VERSION ""

NS_ :

BS_:

BU_: C50 TC_GPS_TELEM PDM MM5 DRIVERDISPLAY M400

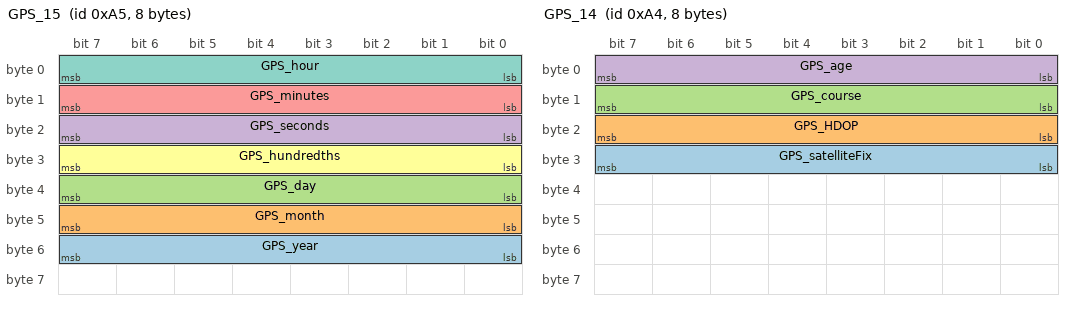
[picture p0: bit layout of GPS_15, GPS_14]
BO_ 165 GPS_15: 8 Vector__XXX
 SG_ GPS_year : 48|8@1+ (1,0) [0|0] "" Vector__XXX
 SG_ GPS_month : 40|8@1+ (1,0) [0|0] "" Vector__XXX
 SG_ GPS_day : 32|8@1+ (1,0) [0|0] "" Vector__XXX
 SG_ GPS_seconds : 16|8@1+ (1,0) [0|0] "secs" Vector__XXX
 SG_ GPS_minutes : 8|8@1+ (1,0) [0|0] "mins" Vector__XXX
 SG_ GPS_hundredths : 24|8@1+ (1,0) [0|0] "" Vector__XXX
 SG_ GPS_hour : 0|8@1+ (1,0) [0|0] "hrs" Vector__XXX

BO_ 164 GPS_14: 8 Vector__XXX
 SG_ GPS_satelliteFix : 24|8@1+ (1,0) [0|0] "" Vector__XXX
 SG_ GPS_HDOP : 16|8@1+ (1,0) [0|0] "" Vector__XXX
 SG_ GPS_course : 8|8@1+ (1,0) [0|0] "" Vector__XXX
 SG_ GPS_age : 0|8@1+ (1,0) [0|0] "" Vector__XXX

BO_ 163 GPS_13: 8 Vector__XXX
 SG_ GPS_speed : 32|32@1+ (1,0) [0|0] "mph" Vector__XXX
 SG_ GPS_longitude : 0|32@1- (1,0) [0|0] "degrees" Vector__XXX

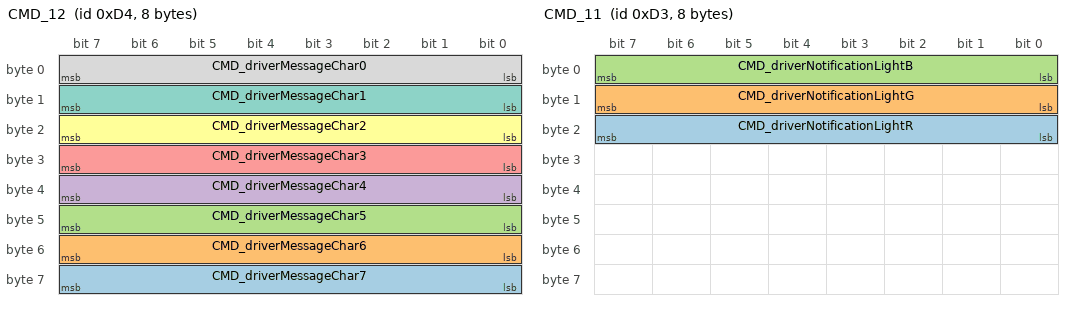
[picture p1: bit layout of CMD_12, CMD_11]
BO_ 212 CMD_12: 8 Vector__XXX
 SG_ CMD_driverMessageChar7 : 56|8@1+ (1,0) [0|255] "Duty Cycle" Vector__XXX
 SG_ CMD_driverMessageChar6 : 48|8@1+ (1,0) [0|255] "Duty Cycle" Vector__XXX
 SG_ CMD_driverMessageChar5 : 40|8@1+ (1,0) [0|255] "Duty Cycle" Vector__XXX
 SG_ CMD_driverMessageChar4 : 32|8@1+ (1,0) [0|255] "Duty Cycle" Vector__XXX
 SG_ CMD_driverMessageChar3 : 24|8@1+ (1,0) [0|255] "Duty Cycle" Vector__XXX
 SG_ CMD_driverMessageChar2 : 16|8@1+ (1,0) [0|255] "Duty Cycle" Vector__XXX
 SG_ CMD_driverMessageChar1 : 8|8@1+ (1,0) [0|255] "Duty Cycle" Vector__XXX
 SG_ CMD_driverMessageChar0 : 0|8@1+ (1,0) [0|255] "Duty Cycle" Vector__XXX

BO_ 211 CMD_11: 8 Vector__XXX
 SG_ CMD_driverNotificationLightR : 16|8@1+ (1,0) [0|255] "Duty Cycle" Vector__XXX
 SG_ CMD_driverNotificationLightG : 8|8@1+ (1,0) [0|255] "Duty Cycle" Vector__XXX
 SG_ CMD_driverNotificationLightB : 0|8@1+ (1,0) [0|255] "Duty Cycle" Vector__XXX

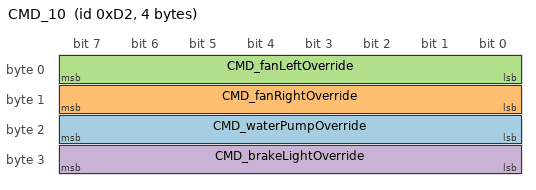
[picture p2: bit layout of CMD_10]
BO_ 210 CMD_10: 4 Vector__XXX
 SG_ CMD_waterPumpOverride : 16|8@1- (1,0) [0|100] "Duty Cycle" Vector__XXX
 SG_ CMD_fanRightOverride : 8|8@1- (1,0) [0|100] "Duty Cycle" Vector__XXX
 SG_ CMD_fanLeftOverride : 0|8@1- (1,0) [0|100] "Duty Cycle" Vector__XXX
 SG_ CMD_brakeLightOverride : 24|8@1- (1,0) [0|100] "Duty Cycle" Vector__XXX

BO_ 162 GPS_12: 8 Vector__XXX
 SG_ GPS_altitude : 32|32@1+ (1,0) [0|0] "m" Vector__XXX
 SG_ GPS_latitude : 0|32@1- (1,0) [0|0] "degrees" Vector__XXX

BO_ 120 C50_m400Data: 8 Vector__XXX
 SG_ C50rowCounterM400Data M : 7|8@0+ (1,0) [0|255] "" Vector__XXX
 SG_ C50_tcSet m1 : 55|16@0- (1,0) [0|0] "" Vector__XXX
 SG_ C50_mm5YawRate m1 : 39|16@0- (0.01,0) [0|0] "" Vector__XXX
 SG_ C50_m400ExhaustGasTemp4 m1 : 23|16@0- (0.1,0) [0|0] "" Vector__XXX
 SG_ C50_m400ExhaustGasTemp3 m0 : 55|16@0- (0.1,0) [0|0] "" Vector__XXX
 SG_ C50_m400ExhaustGasTemp2 m0 : 39|16@0- (0.1,0) [0|0] "" Vector__XXX
 SG_ C50_m400ExhaustGasTemp1 m0 : 23|16@0- (0.1,0) [0|0] "" Vector__XXX

BO_ 161 VCU_11: 8 Vector__XXX
 SG_ VCU_laptrigger : 0|8@1- (1,0) [0|0] "bool" Vector__XXX

BO_ 380 MM5_02: 8 MM5
 SG_ MM5_Az : 32|16@1+ (-0.0001274,-4.1745795) [0|0] "" Vector__XXX

BO_ 376 MM5_01: 8 MM5
 SG_ MM5_rollRate : 0|16@1+ (-0.005,163.9) [0|0] "" Vector__XXX
 SG_ MM5_Ax : 32|16@1+ (-0.0001274,4.1745795) [0|0] "" Vector__XXX

BO_ 372 MM5_00: 8 MM5
 SG_ MM5_yawRate : 0|16@1+ (0.005,-163.9) [0|0] "" Vector__XXX
 SG_ MM5_Ay : 32|16@1+ (-0.0001274,4.1745795) [0|0] "" Vector__XXX

BO_ 101 M400_dataSet2: 8 M400
 SG_ M400_oilTemp m16 : 23|16@0- (0.1,0) [-3276.8|3276.7] "C" Vector__XXX
 SG_ M400_oilPressure m15 : 55|16@0- (0.1,0) [-3276.8|3276.7] "PSI" Vector__XXX
 SG_ M400_manifoldPressure m15 : 39|16@0- (0.1,0) [-3276.8|3276.7] "kPa" Vector__XXX
 SG_ M400_la1LongTermTrim m15 : 23|16@0- (0.1,0) [-3276.8|3276.7] "" Vector__XXX
 SG_ M400_inletAirTemp m14 : 55|16@0- (0.1,0) [-3276.8|3276.7] "C" Vector__XXX
 SG_ M400_ignMapComp m14 : 39|16@0- (0.1,0) [-3276.8|3276.7] "deg" Vector__XXX
 SG_ M400_ignEtComp m14 : 23|16@0- (0.1,0) [-3276.8|3276.7] "deg" Vector__XXX
 SG_ M400_ignComp2 m13 : 55|16@0- (0.1,0) [-3276.8|3276.7] "deg" Vector__XXX
 SG_ M400_ignComp1 m13 : 39|16@0- (0.1,0) [-3276.8|3276.7] "deg" Vector__XXX
 SG_ M400_ignBaseAdvance m13 : 23|16@0- (0.1,0) [-3276.8|3276.7] "deg" Vector__XXX
 SG_ M400_ignAtComp m12 : 55|16@0- (0.1,0) [-3276.8|3276.7] "deg" Vector__XXX
 SG_ M400_ign4Advance m12 : 39|16@0- (0.1,0) [-3276.8|3276.7] "deg" Vector__XXX
 SG_ M400_ign3Advance m12 : 23|16@0- (0.1,0) [-3276.8|3276.7] "deg" Vector__XXX
 SG_ M400_ign2Advance m11 : 55|16@0- (0.1,0) [-3276.8|3276.7] "deg" Vector__XXX
 SG_ M400_ign1Advance m11 : 39|16@0- (0.1,0) [-3276.8|3276.7] "deg" Vector__XXX
 SG_ M400_fuelUsed m11 : 23|16@0- (1,0) [-32768|32767] "" Vector__XXX
 SG_ M400_fuelTemp m10 : 55|16@0- (0.1,0) [-3276.8|3276.7] "C" Vector__XXX
 SG_ M400_fuelStartingComp m10 : 39|16@0- (0.1,0) [-3276.8|3276.7] "%" Vector__XXX
 SG_ M400_fuelPressure m10 : 23|16@0- (0.1,0) [-3276.8|3276.7] "PSI" Vector__XXX
 SG_ M400_fuelMapComp m9 : 55|16@0- (0.1,0) [0|0] "%" Vector__XXX
 SG_ M400_fuelLambdaComp m9 : 39|16@0- (1,0) [-32768|32767] "%" Vector__XXX
 SG_ M400_fuelInjDutyCycle m9 : 23|16@0- (0.1,0) [-3276.8|3276.7] "%" Vector__XXX
 SG_ M400_fuelFtComp m8 : 55|16@0- (0.1,0) [-3276.8|3276.7] "%" Vector__XXX
 SG_ M400_fuelFpComp m8 : 39|16@0- (0.1,0) [-3276.8|3276.7] "%" Vector__XXX
 SG_ M400_fuelEtComp m8 : 23|16@0- (0.1,0) [-3276.8|3276.7] "%" Vector__XXX
 SG_ M400_fuelComp2 m7 : 55|16@0- (0.1,0) [-3276.8|3276.7] "%" Vector__XXX
 SG_ M400_fuelComp1 m7 : 39|16@0- (0.1,0) [-3276.8|3276.7] "%" Vector__XXX
 SG_ M400_fuelAtComp m7 : 23|16@0- (0.1,0) [-3276.8|3276.7] "%" Vector__XXX
 SG_ M400_fuelActualPulseW m6 : 55|16@0- (0.002,0) [-65.536|65.534] "ms" Vector__XXX
 SG_ M400_fuel4IndivTrim m6 : 39|16@0- (1,0) [-32768|32767] "%" Vector__XXX
 SG_ M400_fuel3IndivTrim m6 : 23|16@0- (1,0) [-32768|32767] "%" Vector__XXX
 SG_ M400_fuel2IndivTrim m5 : 55|16@0- (1,0) [-32768|32767] "%" Vector__XXX
 SG_ M400_fuel1IndivTrim m5 : 39|16@0- (1,0) [-32768|32767] "%" Vector__XXX
 SG_ M400_exhaustGasTemp4 m5 : 23|16@0- (1,0) [-32768|32767] "C" Vector__XXX
 SG_ M400_exhaustGasTemp3 m4 : 55|16@0- (1,0) [-32768|32767] "C" Vector__XXX
 SG_ M400_exhaustGasTemp2 m4 : 39|16@0- (1,0) [-32768|32767] "C" Vector__XXX
 SG_ M400_exhaustGasTemp1 m4 : 23|16@0- (1,0) [-32768|32767] "C" Vector__XXX
 SG_ M400_engineTemp m3 : 55|16@0- (0.1,0) [-3276.8|3276.7] "C" Vector__XXX
 SG_ M400_ecuInternalTemp m3 : 39|16@0- (0.1,0) [-3276.8|3276.7] "C" Vector__XXX
 SG_ M400_ecuCpuUsage m3 : 23|16@0- (0.1,0) [-3276.8|3276.7] "%" Vector__XXX
 SG_ M400_batteryVoltage m2 : 55|16@0- (0.01,0) [-327.68|327.67] "V" Vector__XXX
 SG_ M400_auxOut8DutyCycle m2 : 39|16@0- (1,0) [-32768|32767] "%" Vector__XXX
 SG_ M400_auxOut7DutyCycle m2 : 23|16@0- (1,0) [-32768|32767] "%" Vector__XXX
 SG_ M400_auxOut6DutyCycle m1 : 55|16@0- (1,0) [-32768|32767] "%" Vector__XXX
 SG_ M400_auxOut5DutyCycle m1 : 39|16@0- (1,0) [-32768|32767] "%" Vector__XXX
 SG_ M400_auxOut4DutyCycle m1 : 23|16@0- (1,0) [-32768|32767] "%" Vector__XXX
 SG_ M400_auxOut3DutyCycle m0 : 55|16@0- (1,0) [-32768|32767] "%" Vector__XXX
 SG_ M400_auxOut2DutyCycle m0 : 39|16@0- (1,0) [-32768|32767] "%" Vector__XXX
 SG_ M400_auxOut1DutyCycle m0 : 23|16@0- (1,0) [-32768|32767] "%" Vector__XXX
 SG_ M400_rowCounterDataSet2 M : 0|8@1+ (1,0) [0|255] "" Vector__XXX

BO_ 100 M400_dataSet1: 8 M400
 SG_ M400_lambda1 m7 : 55|16@0- (0.001,0) [-32.768|32.767] "" Vector__XXX
 SG_ M400_la1ShortTermTrim m7 : 39|16@0- (0.01,0) [-327.68|327.67] "" Vector__XXX
 SG_ M400_la1AimValue m7 : 23|16@0- (0.001,0) [-32.768|32.767] "" Vector__XXX
 SG_ M400_ignOverallTrim m6 : 55|16@0- (1,0) [-32768|32767] "deg" Vector__XXX
 SG_ M400_fuelOverallTrim m6 : 39|16@0- (0.1,0) [-3276.8|3276.7] "%" Vector__XXX
 SG_ M400_fuelCutLevelTotal m6 : 23|16@0- (0.1,0) [-3276.8|3276.7] "%" Vector__XXX
 SG_ M400_gearSensorVoltage m5 : 55|16@0- (0.001,0) [-32.768|32.767] "V" Vector__XXX
 SG_ M400_gearDet m5 : 39|16@0- (1,0) [-32768|32767] "" Vector__XXX
 SG_ M400_gear m5 : 23|16@0- (1,0) [-32768|32767] "" Vector__XXX
 SG_ M400_throttlePosition m4 : 55|16@0- (0.1,0) [-3276.8|3276.7] "%" Vector__XXX
 SG_ M400_rpm m4 : 39|16@0- (1,0) [-32768|32767] "RPM" Vector__XXX
 SG_ M400_ignCutLevelTotal m4 : 23|16@0- (1,0) [-32768|32767] "%" Vector__XXX
 SG_ M400_wheelSlip m3 : 55|16@0- (0.1,0) [-3276.8|3276.7] "%" Vector__XXX
 SG_ M400_tcSlipAimValue m3 : 39|16@0- (0.1,0) [-3276.8|3276.7] "" Vector__XXX
 SG_ M400_tcSlipAimError m3 : 23|16@0- (0.1,0) [-3276.8|3276.7] "" Vector__XXX
 SG_ M400_tcPowerReduction m2 : 55|16@0- (0.1,0) [0|75] "%" Vector__XXX
 SG_ M400_tcLaunchAimRPM m2 : 39|16@0- (1,0) [-32768|32767] "RPM" Vector__XXX
 SG_ M400_tcIgnretard m2 : 23|16@0- (1,0) [-32768|32767] "deg" Vector__XXX
 SG_ M400_groundSpeedRight m1 : 55|16@0- (0.1,0) [-3276.8|3276.7] "MPH" Vector__XXX
 SG_ M400_groundSpeedLeft m1 : 39|16@0- (0.1,0) [-3276.8|3276.7] "MPH" Vector__XXX
 SG_ M400_groundSpeed m1 : 23|16@0- (0.1,0) [-3276.8|3276.7] "MPH" Vector__XXX
 SG_ M400_driveSpeedRight m0 : 55|16@0- (0.1,0) [-3276.8|3276.7] "MPH" Vector__XXX
 SG_ M400_driveSpeedLeft m0 : 39|16@0- (0.1,0) [-3276.8|3276.7] "MPH" Vector__XXX
 SG_ M400_driveSpeed m0 : 23|16@0- (0.1,0) [-3276.8|3276.7] "MPH" Vector__XXX
 SG_ M400_rowCounterDataSet1 M : 0|8@1+ (1,0) [0|255] "" Vector__XXX

CM_ SG_ 165 GPS_year "Year";
CM_ SG_ 165 GPS_month "Month";
CM_ SG_ 165 GPS_day "Day";
CM_ SG_ 165 GPS_seconds "Seconds";
CM_ SG_ 165 GPS_minutes "Minutes";
CM_ SG_ 165 GPS_hundredths "Hundredths";
CM_ SG_ 165 GPS_hour "Hour";
CM_ SG_ 164 GPS_satelliteFix "Number of satellite fixes";
CM_ SG_ 164 GPS_HDOP "HDOP";
CM_ SG_ 164 GPS_course "Course card (or speed)";
CM_ SG_ 164 GPS_age "Age of GPS fix";
CM_ SG_ 163 GPS_speed "Ground speed (kph)";
CM_ SG_ 163 GPS_longitude "Longitude
";
CM_ BO_ 162 "gps lattitude and longitude";
CM_ SG_ 162 GPS_altitude "Altitude (meters)";
CM_ SG_ 162 GPS_latitude "Latitude";
CM_ SG_ 120 C50rowCounterM400Data "Multiplexer Row Counter for M400 Custom Data Set 2";
CM_ SG_ 161 VCU_laptrigger "100 = sucess";
CM_ SG_ 101 M400_oilTemp "Oil Temp ";
CM_ SG_ 101 M400_oilPressure "Oil Pressure ";
CM_ SG_ 101 M400_manifoldPressure "Manifold Pressure ";
CM_ SG_ 101 M400_la1LongTermTrim "La1 Long Term Trim ";
CM_ SG_ 101 M400_inletAirTemp "Inlet Air Temp ";
CM_ SG_ 101 M400_ignMapComp "Ign MAP Comp ";
CM_ SG_ 101 M400_ignEtComp "Ign ET Comp ";
CM_ SG_ 101 M400_ignComp2 "Ign Comp 2 ";
CM_ SG_ 101 M400_ignComp1 "Ign Comp 1 ";
CM_ SG_ 101 M400_ignBaseAdvance "Ign Base Advance ";
CM_ SG_ 101 M400_ignAtComp "Ign AT Comp ";
CM_ SG_ 101 M400_ign4Advance "Ign 4 Advance ";
CM_ SG_ 101 M400_ign3Advance "Ign 3 Advance ";
CM_ SG_ 101 M400_ign2Advance "Ign 2 Advance ";
CM_ SG_ 101 M400_ign1Advance "Ign 1 Advance ";
CM_ SG_ 101 M400_fuelUsed "Fuel Used ";
CM_ SG_ 101 M400_fuelTemp "Fuel Temp ";
CM_ SG_ 101 M400_fuelStartingComp "Fuel Starting Comp ";
CM_ SG_ 101 M400_fuelPressure "Fuel Pressure ";
CM_ SG_ 101 M400_fuelMapComp "Fuel MAP Comp ";
CM_ SG_ 101 M400_fuelLambdaComp "Fuel Lambda Comp ";
CM_ SG_ 101 M400_fuelInjDutyCycle "Fuel Inj Duty Cycle ";
CM_ SG_ 101 M400_fuelFtComp "Fuel FT Comp ";
CM_ SG_ 101 M400_fuelFpComp "Fuel FP Comp ";
CM_ SG_ 101 M400_fuelEtComp "Fuel ET Comp ";
CM_ SG_ 101 M400_fuelComp2 "Fuel Comp 2";
CM_ SG_ 101 M400_fuelComp1 "Fuel Comp 1 ";
CM_ SG_ 101 M400_fuelAtComp "Fuel AT Comp ";
CM_ SG_ 101 M400_fuelActualPulseW "Fuel Actual Pulse W ";
CM_ SG_ 101 M400_fuel4IndivTrim "Fuel 4 Indiv Trim ";
CM_ SG_ 101 M400_fuel3IndivTrim "Fuel 3 Indiv Trim";
CM_ SG_ 101 M400_fuel2IndivTrim "Fuel 2 Indiv Trim ";
CM_ SG_ 101 M400_fuel1IndivTrim "Fuel 1 Indiv Trim ";
CM_ SG_ 101 M400_exhaustGasTemp4 "Exhaust Gas Temp 4";
CM_ SG_ 101 M400_exhaustGasTemp3 "Exhaust Gas Temp 3";
CM_ SG_ 101 M400_exhaustGasTemp2 "Exhaust Gas Temp 2";
CM_ SG_ 101 M400_exhaustGasTemp1 "Exhaust Gas Temp 1";
CM_ SG_ 101 M400_engineTemp "Engine Temp ";
CM_ SG_ 101 M400_ecuInternalTemp "ECU Internal Temp ";
CM_ SG_ 101 M400_ecuCpuUsage "ECU CPU Usage ";
CM_ SG_ 101 M400_batteryVoltage "Battery Voltage";
CM_ SG_ 101 M400_auxOut8DutyCycle "Aux Out8 Duty Cycle";
CM_ SG_ 101 M400_auxOut7DutyCycle "Aux Out7 Duty Cycle ";
CM_ SG_ 101 M400_auxOut6DutyCycle "Aux Out6 Duty Cycle";
CM_ SG_ 101 M400_auxOut5DutyCycle "Aux Out5 Duty Cycle";
CM_ SG_ 101 M400_auxOut4DutyCycle "Aux Out4 Duty Cycle";
CM_ SG_ 101 M400_auxOut3DutyCycle "Aux Out3 Duty Cycle";
CM_ SG_ 101 M400_auxOut2DutyCycle "Aux Out2 Duty Cycle";
CM_ SG_ 101 M400_auxOut1DutyCycle "Aux Out1 Duty Cycle";
CM_ SG_ 101 M400_rowCounterDataSet2 "Multiplexer Row Counter for M400 Custom Data Set 2";
CM_ SG_ 100 M400_lambda1 "Lambda 1  ";
CM_ SG_ 100 M400_la1ShortTermTrim "La1 Short Term Trim ";
CM_ SG_ 100 M400_la1AimValue "La1 Aim Value ";
CM_ SG_ 100 M400_ignOverallTrim "Ign Overall Trim ";
CM_ SG_ 100 M400_fuelOverallTrim "Fuel Overall Trim ";
CM_ SG_ 100 M400_fuelCutLevelTotal "Fuel Cut Level Total 
";
CM_ SG_ 100 M400_gearSensorVoltage "Gear Sensor Voltage";
CM_ SG_ 100 M400_gearDet "Gear Det ";
CM_ SG_ 100 M400_gear "Gear";
CM_ SG_ 100 M400_throttlePosition "Throttle Position ";
CM_ SG_ 100 M400_rpm "RPM";
CM_ SG_ 100 M400_ignCutLevelTotal "Ign Cut Level Total ";
CM_ SG_ 100 M400_wheelSlip "Wheel Slip";
CM_ SG_ 100 M400_tcSlipAimValue "TC Slip Aim Value";
CM_ SG_ 100 M400_tcSlipAimError "TC Slip Aim Error";
CM_ SG_ 100 M400_tcPowerReduction "TC Power Reduction";
CM_ SG_ 100 M400_tcLaunchAimRPM "TC Launch Aim RPM";
CM_ SG_ 100 M400_tcIgnretard "TC Ign Retard";
CM_ SG_ 100 M400_groundSpeedRight "Ground Speed Right";
CM_ SG_ 100 M400_groundSpeedLeft "Ground Speed Left";
CM_ SG_ 100 M400_groundSpeed "Ground Speed";
CM_ SG_ 100 M400_driveSpeedRight "Drive Speed Right";
CM_ SG_ 100 M400_driveSpeedLeft "Drive Speed Left";
CM_ SG_ 100 M400_driveSpeed "Drive Speed
";
CM_ SG_ 100 M400_rowCounterDataSet1 "Multiplexer Row Counter for M400 Custom Data Set 1";
